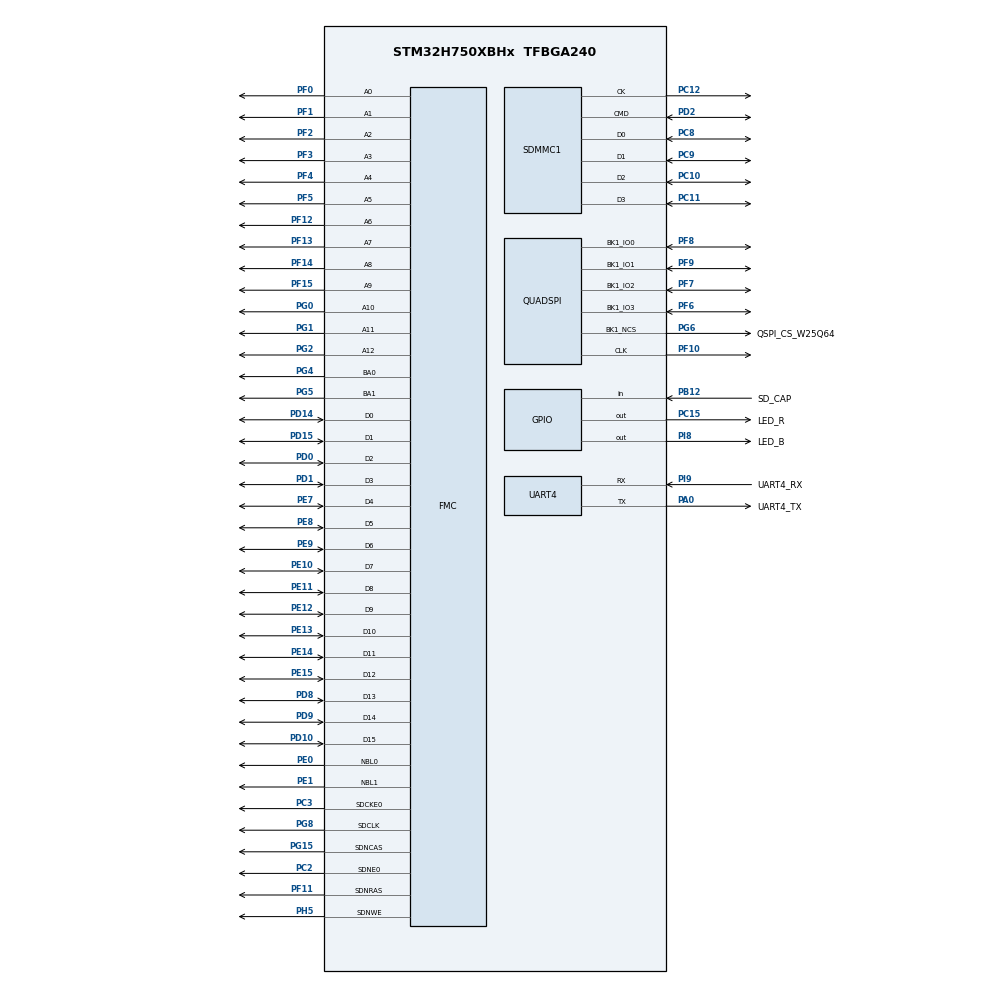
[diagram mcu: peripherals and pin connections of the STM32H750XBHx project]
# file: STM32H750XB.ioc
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CORTEX_M7.CPU_DCache=Enabled
CORTEX_M7.CPU_ICache=Enabled
CORTEX_M7.default_mode_Activation=0
FATFS.BSP.number=1
FATFS.USE_DMA_CODE_SD=0
FATFS._CODE_PAGE=437
FATFS._USE_LFN=3
FATFS0.BSP.STBoard=false
FATFS0.BSP.api=Unknown
FATFS0.BSP.instance=PB12
FATFS0.BSP.ip=GPIO
FATFS0.BSP.mode=Input
FATFS0.BSP.name=Detect_SDIO
FATFS0.BSP.solution=PB12
FMC.CASLatency1=FMC_SDRAM_CAS_LATENCY_2
FMC.ColumnBitsNumber1=FMC_SDRAM_COLUMN_BITS_NUM_9
FMC.SDClockPeriod1=FMC_SDRAM_CLOCK_PERIOD_2
Mcu.Family=STM32H7
Mcu.Name=STM32H750XBHx
Mcu.Package=TFBGA240
NVIC.PriorityGroup=NVIC_PRIORITYGROUP_4
PA0.GPIO_Label=UART4_TX
PA0.Mode=Asynchronous
PA0.Signal=UART4_TX
PB12.GPIO_Label=SD_CAP
PB12.GPIO_PuPd=GPIO_PULLDOWN
PB12.Signal=GPIO_Input
PC10.Mode=SD_4_bits_Wide_bus
PC10.Signal=SDMMC1_D2
PC11.Mode=SD_4_bits_Wide_bus
PC11.Signal=SDMMC1_D3
PC12.Mode=SD_4_bits_Wide_bus
PC12.Signal=SDMMC1_CK
PC15-OSC32_OUT\ (OSC32_OUT).GPIO_Label=LED_R
PC15-OSC32_OUT\ (OSC32_OUT).GPIO_PuPd=GPIO_PULLUP
PC15-OSC32_OUT\ (OSC32_OUT).PinState=GPIO_PIN_SET
PC15-OSC32_OUT\ (OSC32_OUT).Signal=GPIO_Output
PC2.Mode=SdramChipSelect1_1
PC2.Signal=FMC_SDNE0
PC3.Mode=SdramChipSelect1_1
PC3.Signal=FMC_SDCKE0
PC8.Mode=SD_4_bits_Wide_bus
PC8.Signal=SDMMC1_D0
PC9.Mode=SD_4_bits_Wide_bus
PC9.Signal=SDMMC1_D1
PD0.Signal=FMC_D2_DA2
PD1.Signal=FMC_D3_DA3
PD10.Signal=FMC_D15_DA15
PD14.Signal=FMC_D0_DA0
PD15.Signal=FMC_D1_DA1
PD2.Mode=SD_4_bits_Wide_bus
PD2.Signal=SDMMC1_CMD
PD8.Signal=FMC_D13_DA13
PD9.Signal=FMC_D14_DA14
PE0.Signal=FMC_NBL0
PE1.Signal=FMC_NBL1
PE10.Signal=FMC_D7_DA7
PE11.Signal=FMC_D8_DA8
PE12.Signal=FMC_D9_DA9
PE13.Signal=FMC_D10_DA10
PE14.Signal=FMC_D11_DA11
PE15.Signal=FMC_D12_DA12
PE7.Signal=FMC_D4_DA4
PE8.Signal=FMC_D5_DA5
PE9.Signal=FMC_D6_DA6
PF0.Signal=FMC_A0
PF1.Signal=FMC_A1
PF10.GPIO_Speed=GPIO_SPEED_FREQ_VERY_HIGH
PF10.Mode=Single Bank 1
PF10.Signal=QUADSPI_CLK
PF11.Signal=FMC_SDNRAS
PF12.Signal=FMC_A6
PF13.Signal=FMC_A7
PF14.Signal=FMC_A8
PF15.Signal=FMC_A9
PF2.Signal=FMC_A2
PF3.Signal=FMC_A3
PF4.Signal=FMC_A4
PF5.Signal=FMC_A5
PF6.GPIO_Speed=GPIO_SPEED_FREQ_VERY_HIGH
PF6.Mode=Single Bank 1
PF6.Signal=QUADSPI_BK1_IO3
PF7.GPIO_Speed=GPIO_SPEED_FREQ_VERY_HIGH
PF7.Mode=Single Bank 1
PF7.Signal=QUADSPI_BK1_IO2
PF8.GPIO_Speed=GPIO_SPEED_FREQ_VERY_HIGH
PF8.Mode=Single Bank 1
PF8.Signal=QUADSPI_BK1_IO0
PF9.GPIO_Speed=GPIO_SPEED_FREQ_VERY_HIGH
PF9.Mode=Single Bank 1
PF9.Signal=QUADSPI_BK1_IO1
PG0.Signal=FMC_A10
PG1.Signal=FMC_A11
PG15.Signal=FMC_SDNCAS
PG2.Signal=FMC_A12
PG4.Signal=FMC_A14_BA0
PG5.Signal=FMC_A15_BA1
PG6.GPIO_Label=QSPI_CS_W25Q64
PG6.GPIO_PuPd=GPIO_PULLUP
PG6.GPIO_Speed=GPIO_SPEED_FREQ_VERY_HIGH
PG6.Mode=Single Bank 1
PG6.Signal=QUADSPI_BK1_NCS
PG8.Signal=FMC_SDCLK
PH0-OSC_IN\ (PH0).Mode=HSE-External-Oscillator
PH0-OSC_IN\ (PH0).Signal=RCC_OSC_IN
PH1-OSC_OUT\ (PH1).Mode=HSE-External-Oscillator
PH1-OSC_OUT\ (PH1).Signal=RCC_OSC_OUT
PH5.GPIO_PuPd=GPIO_PULLDOWN
PH5.Signal=FMC_SDNWE
PI8.GPIO_Label=LED_B
PI8.Signal=GPIO_Output
PI9.GPIO_Label=UART4_RX
PI9.Mode=Asynchronous
PI9.Signal=UART4_RX
ProjectManager.HeapSize=0x800
ProjectManager.StackSize=0x800
ProjectManager.TargetToolchain=MDK-ARM V5.27
QUADSPI.ClockMode=QSPI_CLOCK_MODE_3
QUADSPI.ClockPrescaler=5
QUADSPI.FifoThreshold=4
QUADSPI.FlashSize=22
RCC.ADCFreq_Value=50000000
RCC.APB1Freq_Value=120000000
RCC.APB2Freq_Value=120000000
RCC.APB3Freq_Value=120000000
RCC.APB4Freq_Value=120000000
RCC.CortexFreq_Value=480000000
RCC.D1PPRE=RCC_APB3_DIV2
RCC.D2PPRE1=RCC_APB1_DIV2
RCC.D2PPRE2=RCC_APB2_DIV2
RCC.D3PPRE=RCC_APB4_DIV2
RCC.DIVM1=5
RCC.DIVM2=2
RCC.DIVM3=5
RCC.DIVN1=192
RCC.DIVN2=16
RCC.DIVN3=50
RCC.DIVP2=4
RCC.DIVP3=1
RCC.DIVQ2=1
RCC.DIVQ3=5
RCC.DIVR3=10
RCC.HCLKFreq_Value=240000000
RCC.HPRE=RCC_HCLK_DIV2
RCC.PLL2FRACN=0
RCC.PLLFRACN=0
RCC.PLLSourceVirtual=RCC_PLLSOURCE_HSE
RCC.ProductRev=revV
RCC.SDMMC1CLockSelection=RCC_SDMMCCLKSOURCE_PLL2
RCC.SPI123CLockSelection=RCC_SPI123CLKSOURCE_PLL2
RCC.SYSCLKFreq_VALUE=480000000
RCC.SYSCLKSource=RCC_SYSCLKSOURCE_PLLCLK
RCC.USBCLockSelection=RCC_USBCLKSOURCE_PLL3
RCC.USBFreq_Value=50000000
SDMMC1.ClockDiv=2
SH.FMC_A0.0=FMC_A0,13b-sda1
SH.FMC_A1.0=FMC_A1,13b-sda1
SH.FMC_A10.0=FMC_A10,13b-sda1
SH.FMC_A11.0=FMC_A11,13b-sda1
SH.FMC_A12.0=FMC_A12,13b-sda1
SH.FMC_A14_BA0.0=FMC_BA0,FourSdramBanks1
SH.FMC_A15_BA1.0=FMC_BA1,FourSdramBanks1
SH.FMC_A2.0=FMC_A2,13b-sda1
SH.FMC_A3.0=FMC_A3,13b-sda1
SH.FMC_A4.0=FMC_A4,13b-sda1
SH.FMC_A5.0=FMC_A5,13b-sda1
SH.FMC_A6.0=FMC_A6,13b-sda1
SH.FMC_A7.0=FMC_A7,13b-sda1
SH.FMC_A8.0=FMC_A8,13b-sda1
SH.FMC_A9.0=FMC_A9,13b-sda1
SH.FMC_D0_DA0.0=FMC_D0,sd-16b-d1
SH.FMC_D10_DA10.0=FMC_D10,sd-16b-d1
SH.FMC_D11_DA11.0=FMC_D11,sd-16b-d1
SH.FMC_D12_DA12.0=FMC_D12,sd-16b-d1
SH.FMC_D13_DA13.0=FMC_D13,sd-16b-d1
SH.FMC_D14_DA14.0=FMC_D14,sd-16b-d1
SH.FMC_D15_DA15.0=FMC_D15,sd-16b-d1
SH.FMC_D1_DA1.0=FMC_D1,sd-16b-d1
SH.FMC_D2_DA2.0=FMC_D2,sd-16b-d1
SH.FMC_D3_DA3.0=FMC_D3,sd-16b-d1
SH.FMC_D4_DA4.0=FMC_D4,sd-16b-d1
SH.FMC_D5_DA5.0=FMC_D5,sd-16b-d1
SH.FMC_D6_DA6.0=FMC_D6,sd-16b-d1
SH.FMC_D7_DA7.0=FMC_D7,sd-16b-d1
SH.FMC_D8_DA8.0=FMC_D8,sd-16b-d1
SH.FMC_D9_DA9.0=FMC_D9,sd-16b-d1
SH.FMC_NBL0.0=FMC_NBL0,Sd2ByteEnable1
SH.FMC_NBL1.0=FMC_NBL1,Sd2ByteEnable1
SH.FMC_SDCLK.0=FMC_SDCLK,13b-sda1
SH.FMC_SDNCAS.0=FMC_SDNCAS,13b-sda1
SH.FMC_SDNRAS.0=FMC_SDNRAS,13b-sda1
SH.FMC_SDNWE.0=FMC_SDNWE,13b-sda1
VP_FATFS_VS_SDIO.Mode=SDIO
board=custom

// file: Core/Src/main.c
/* USER CODE BEGIN Header */
/**
  ******************************************************************************
  * @file           : main.c
  * @brief          : Main program body
  ******************************************************************************
  * @attention
  *
  * Copyright (c) 2023 STMicroelectronics.
  * All rights reserved.
  *
  * This software is licensed under terms that can be found in the LICENSE file
  * in the root directory of this software component.
  * If no LICENSE file comes with this software, it is provided AS-IS.
  *
  ******************************************************************************
  */
/* USER CODE END Header */
#include "main.h"
#include "fatfs.h"
#include "quadspi.h"
#include "sdmmc.h"
#include "usart.h"
#include "gpio.h"
#include "fmc.h"

/* USER CODE BEGIN Includes */
#include "boot.h"
/* USER CODE END Includes */

void SystemClock_Config(void);

int main(void)
{

  /* Enable I-Cache---------------------------------------------------------*/
  SCB_EnableICache();

  /* Enable D-Cache---------------------------------------------------------*/
  SCB_EnableDCache();

  /* MCU Configuration--------------------------------------------------------*/

  /* Reset of all peripherals, Initializes the Flash interface and the Systick. */
  HAL_Init();

  /* Configure the system clock */
  SystemClock_Config();

  /* Initialize all configured peripherals */
  MX_GPIO_Init();
  MX_UART4_Init();
  MX_QUADSPI_Init();
  MX_SDMMC1_SD_Init();
  MX_FATFS_Init();
  MX_FMC_Init();
  /* USER CODE BEGIN 2 */
  jump_to_qspi_flash();
  /* USER CODE END 2 */

  /* Infinite loop */
  while (1)
  {

  }
}

void SystemClock_Config(void)
{
  RCC_OscInitTypeDef RCC_OscInitStruct = {0};
  RCC_ClkInitTypeDef RCC_ClkInitStruct = {0};

  /** Supply configuration update enable
  */
  HAL_PWREx_ConfigSupply(PWR_LDO_SUPPLY);

  /** Configure the main internal regulator output voltage
  */
  __HAL_PWR_VOLTAGESCALING_CONFIG(PWR_REGULATOR_VOLTAGE_SCALE1);

  while(!__HAL_PWR_GET_FLAG(PWR_FLAG_VOSRDY)) {}

  __HAL_RCC_SYSCFG_CLK_ENABLE();
  __HAL_PWR_VOLTAGESCALING_CONFIG(PWR_REGULATOR_VOLTAGE_SCALE0);

  while(!__HAL_PWR_GET_FLAG(PWR_FLAG_VOSRDY)) {}

  /** Initializes the RCC Oscillators according to the specified parameters
  * in the RCC_OscInitTypeDef structure.
  */
  RCC_OscInitStruct.OscillatorType = RCC_OSCILLATORTYPE_HSE;
  RCC_OscInitStruct.HSEState = RCC_HSE_ON;
  RCC_OscInitStruct.PLL.PLLState = RCC_PLL_ON;
  RCC_OscInitStruct.PLL.PLLSource = RCC_PLLSOURCE_HSE;
  RCC_OscInitStruct.PLL.PLLM = 5;
  RCC_OscInitStruct.PLL.PLLN = 192;
  RCC_OscInitStruct.PLL.PLLP = 2;
  RCC_OscInitStruct.PLL.PLLQ = 2;
  RCC_OscInitStruct.PLL.PLLR = 2;
  RCC_OscInitStruct.PLL.PLLRGE = RCC_PLL1VCIRANGE_2;
  RCC_OscInitStruct.PLL.PLLVCOSEL = RCC_PLL1VCOWIDE;
  RCC_OscInitStruct.PLL.PLLFRACN = 0;
  if (HAL_RCC_OscConfig(&RCC_OscInitStruct) != HAL_OK)
  {
    Error_Handler();
  }

  /** Initializes the CPU, AHB and APB buses clocks
  */
  RCC_ClkInitStruct.ClockType = RCC_CLOCKTYPE_HCLK|RCC_CLOCKTYPE_SYSCLK
                              |RCC_CLOCKTYPE_PCLK1|RCC_CLOCKTYPE_PCLK2
                              |RCC_CLOCKTYPE_D3PCLK1|RCC_CLOCKTYPE_D1PCLK1;
  RCC_ClkInitStruct.SYSCLKSource = RCC_SYSCLKSOURCE_PLLCLK;
  RCC_ClkInitStruct.SYSCLKDivider = RCC_SYSCLK_DIV1;
  RCC_ClkInitStruct.AHBCLKDivider = RCC_HCLK_DIV2;
  RCC_ClkInitStruct.APB3CLKDivider = RCC_APB3_DIV2;
  RCC_ClkInitStruct.APB1CLKDivider = RCC_APB1_DIV2;
  RCC_ClkInitStruct.APB2CLKDivider = RCC_APB2_DIV2;
  RCC_ClkInitStruct.APB4CLKDivider = RCC_APB4_DIV2;

  if (HAL_RCC_ClockConfig(&RCC_ClkInitStruct, FLASH_LATENCY_4) != HAL_OK)
  {
    Error_Handler();
  }
}

void Error_Handler(void)
{
  __disable_irq();
  while (1)
  {
  }
}
